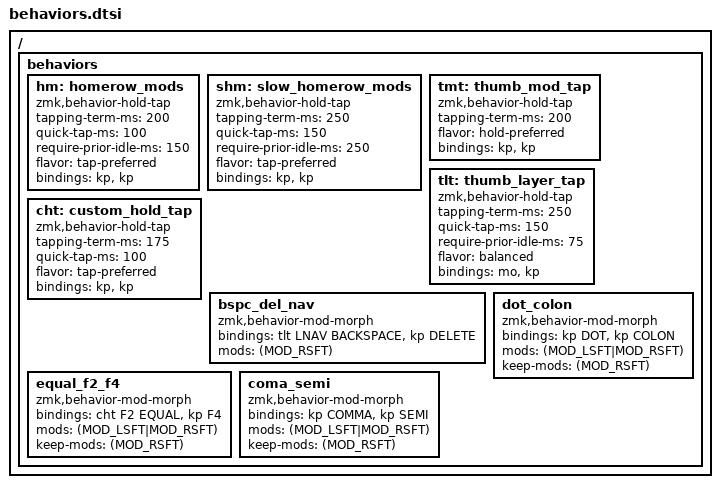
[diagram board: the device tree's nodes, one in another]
// Behaviors shared by every keyboard: hold-taps and mod-morphs used by the layers.
// Requires the layer index defines (LDEF..LSYS) to be defined before this file is included.

/ {
    // ###############################################################################################################################
    // BEHAVIORS #####################################################################################################################
    // ###############################################################################################################################
    behaviors {
        // Hold for HomeRow Mods and Tap for Keys
        hm: homerow_mods {
            compatible = "zmk,behavior-hold-tap";
            #binding-cells = <2>;
            tapping-term-ms = <200>;
            quick-tap-ms = <100>;
            require-prior-idle-ms = <150>;
            flavor = "tap-preferred";
            bindings = <&kp>, <&kp>;
        };

        // Slow Hold for HomeRow Mods and Tap for Keys
        shm: slow_homerow_mods {
            compatible = "zmk,behavior-hold-tap";
            #binding-cells = <2>;
            tapping-term-ms = <250>;
            quick-tap-ms = <150>;
            require-prior-idle-ms = <250>;
            flavor = "tap-preferred";
            bindings = <&kp>, <&kp>;
        };

        // Thumb Hold for Mods and Taps for Keys
        tmt: thumb_mod_tap {
            compatible = "zmk,behavior-hold-tap";
            #binding-cells = <2>;
            tapping-term-ms = <200>;
            flavor = "hold-preferred";
            bindings = <&kp>, <&kp>;
        };

        // Thumb Hold for Layers and Tap for Keys
        tlt: thumb_layer_tap {
            compatible = "zmk,behavior-hold-tap";
            #binding-cells = <2>;
            tapping-term-ms = <250>;
            quick-tap-ms = <150>;
            require-prior-idle-ms = <75>;
            flavor = "balanced";
            bindings = <&mo>, <&kp>;
        };

        // Custom Hold and Tap Behavior
        cht: custom_hold_tap {
            compatible = "zmk,behavior-hold-tap";
            #binding-cells = <2>;
            tapping-term-ms = <175>;
            quick-tap-ms = <100>;
            flavor = "tap-preferred";
            bindings = <&kp>, <&kp>;
        };

        // tap: BACKSPACE | RSHIFT + tap: DELETE
        bspc_del_nav: bspc_del_nav {
            compatible = "zmk,behavior-mod-morph";
            #binding-cells = <0>;
            bindings = <&tlt LNAV BACKSPACE>, <&kp DELETE>;
            mods = <(MOD_RSFT)>;
        };

        // tap: EQUAL | hold: F2 | either SHIFT + tap: F4
        equal_f2_f4: equal_f2_f4 {
            compatible = "zmk,behavior-mod-morph";
            #binding-cells = <0>;
            bindings = <&cht F2 EQUAL>, <&kp F4>;
            mods = <(MOD_LSFT|MOD_RSFT)>;
            keep-mods = <(MOD_RSFT)>;
        };

        // Morphs either SHIFT + DOT into COLON
        dot_colon: dot_colon {
            compatible = "zmk,behavior-mod-morph";
            #binding-cells = <0>;
            bindings = <&kp DOT>, <&kp COLON>;
            mods = <(MOD_LSFT|MOD_RSFT)>;
            keep-mods = <(MOD_RSFT)>;
        };

        // Morphs either SHIFT + COMA into SEMI
        coma_semi: coma_semi {
            compatible = "zmk,behavior-mod-morph";
            #binding-cells = <0>;
            bindings = <&kp COMMA>, <&kp SEMI>;
            mods = <(MOD_LSFT|MOD_RSFT)>;
            keep-mods = <(MOD_RSFT)>;
        };
    };
};
